# SKEAZN642 register map
Vendor: Freescale Semiconductor, Inc.; Series: Kinetis_EA; File version: 1.6
CPU: CM0PLUS r0p0, little endian, no MPU, no FPU, VTOR, 2 interrupt priority bits
Registers are 32-bit, read-write, reset 0x0 unless marked. A register's access mark holds for its fields unless they carry their own. Offsets are from the block's base; [hi:lo] are bit positions; {n}, {i} and the like mark numbered series; 'fields as' and 'values as' point back to an identical list.

## FTMRH_FlashConfig — Flash configuration field
Base 0x00000400; register names take the prefix NV_
{0x0+i} BACKKEY{i} 8-bit ro reset 0xFF (i=0..7) — Backdoor Comparison Key {i}
  [7:0] KEY — Backdoor Comparison Key.
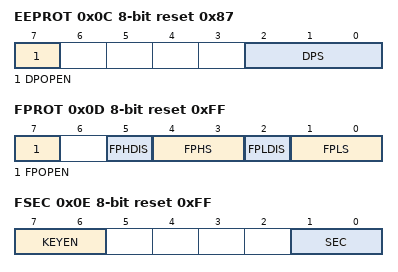
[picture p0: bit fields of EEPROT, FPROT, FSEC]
0x0C EEPROT 8-bit ro reset 0x87 — Non-volatile E-Flash Protection Register
  [7] DPOPEN
    0=Enables EEPROM memory protection; 1=Disables EEPROM memory protection
  [2:0] DPS
    0=Flash address range: 0x00_0000 - 0x00_001F; protected size: 32 bytes; 1=Flash address range: 0x00_0000 - 0x00_003F; protected size: 64 bytes; 2=Flash address range: 0x00_0000 - 0x00_005F; protected size: 96 bytes; 3=Flash address range: 0x00_0000 - 0x00_007F; protected size: 128 bytes; 4=Flash address range: 0x00_0000 - 0x00_009F; protected size: 160 bytes; 5=Flash address range: 0x00_0000 - 0x00_00BF; protected size: 192 bytes; 6=Flash address range: 0x00_0000 - 0x00_00DF; protected size: 224 bytes; 7=Flash address range: 0x00_0000 - 0x00_00FF; protected size: 256 bytes
0x0D FPROT 8-bit ro reset 0xFF — Non-volatile P-Flash Protection Register
  [7] FPOPEN
    0=FPHDIS and FPLDIS bits define unprotected address ranges as specified by the corresponding FPHS and FPLS bits FPROT1.1; 1=FPHDIS and FPLDIS bits enable protection for the address range specified by the corresponding FPHS and FPLS bits
  [5] FPHDIS
    0=Protection/Unprotection enabled; 1=Protection/Unprotection disabled
  [4:3] FPHS
    0=Address range: 0x00_7C00-0x00_7FFF; protected size: 1 KB; 1=Address range: 0x00_7800-0x00_7FFF; protected size: 2 KB; 2=Address range: 0x00_7000-0x00_7FFF; protected size: 4 KB; 3=Address range: 0x00_6000-0x00_7FFF; protected size: 8 KB
  [2] FPLDIS
    values as FPHDIS
  [1:0] FPLS
    0=Address range: 0x00_0000-0x00_07FF; protected size: 2 KB; 1=Address range: 0x00_0000-0x00_0FFF; protected size: 4 KB; 2=Address range: 0x00_0000-0x00_1FFF; protected size: 8 KB; 3=Address range: 0x00_0000-0x00_3FFF; protected size: 16 KB
0x0E FSEC 8-bit ro reset 0xFF — Non-volatile Flash Security Register
  [7:6] KEYEN — Backdoor Key Security Enable
    2=Backdoor key access enabled; 3=Backdoor key access disabled
  [1:0] SEC — Flash Security
    2=MCU security status is unsecure; 3=MCU security status is secure
0x0F FOPT 8-bit ro reset 0xFF — Non-volatile Flash Option Register

## IRQ — Interrupt
Base 0x40031000; register names take the prefix IRQ_
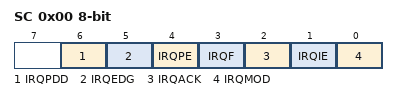
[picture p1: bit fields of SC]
0x00 SC 8-bit — Interrupt Pin Request Status and Control Register
  [6] IRQPDD — Interrupt Request (IRQ) Pull Device Disable
    0=IRQ pull device enabled if IRQPE = 1; 1=IRQ pull device disabled if IRQPE = 1
  [5] IRQEDG — Interrupt Request (IRQ) Edge Select
    0=IRQ is falling-edge or falling-edge/low-level sensitive; 1=IRQ is rising-edge or rising-edge/high-level sensitive
  [4] IRQPE — IRQ Pin Enable
    0=IRQ pin function is disabled; 1=IRQ pin function is enabled
  [3] IRQF ro — IRQ Flag
    0=No IRQ request; 1=IRQ event is detected
  [2] IRQACK wo — IRQ Acknowledge
  [1] IRQIE — IRQ Interrupt Enable
    0=Interrupt request when IRQF set is disabled (use polling); 1=Interrupt requested whenever IRQF = 1
  [0] IRQMOD — IRQ Detection Mode
    0=IRQ event is detected only on falling/rising edges; 1=IRQ event is detected on falling/rising edges and low/high levels

## CRC — Cyclic Redundancy Check
Base 0x40032000; register names take the prefix CRC_
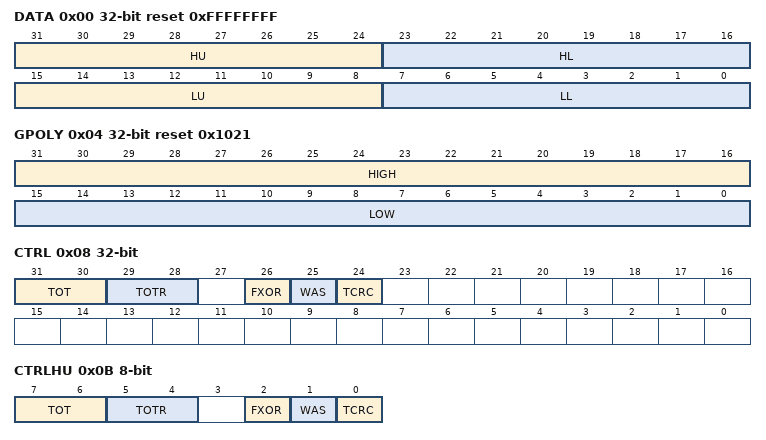
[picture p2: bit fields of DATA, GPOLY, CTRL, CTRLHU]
0x00 DATA reset 0xFFFFFFFF (CRC view) — CRC Data register
  [31:24] HU — CRC High Upper Byte
  [23:16] HL — CRC High Lower Byte
  [15:8] LU — CRC Low Upper Byte
  [7:0] LL — CRC Low Lower Byte
0x00 DATAL 16-bit reset 0xFFFF (CRC view) — CRC_DATAL register.
  [15:0] DATAL — DATAL stores the lower 16 bits of the 16/32 bit CRC
0x00 DATALL 8-bit reset 0xFF (CRC view) — CRC_DATALL register.
  [7:0] DATALL — CRCLL stores the first 8 bits of the 32 bit DATA
0x01 DATALU 8-bit reset 0xFF — CRC_DATALU register.
  [7:0] DATALU — DATALL stores the second 8 bits of the 32 bit CRC
0x02 DATAH 16-bit reset 0xFFFF (CRC view) — CRC_DATAH register.
  [15:0] DATAH — DATAH stores the high 16 bits of the 16/32 bit CRC
0x02 DATAHL 8-bit reset 0xFF (CRC view) — CRC_DATAHL register.
  [7:0] DATAHL — DATAHL stores the third 8 bits of the 32 bit CRC
0x03 DATAHU 8-bit reset 0xFF — CRC_DATAHU register.
  [7:0] DATAHU — DATAHU stores the fourth 8 bits of the 32 bit CRC
0x04 GPOLY reset 0x1021 (CRC view) — CRC Polynomial register
  [31:16] HIGH — High Polynominal Half-word
  [15:0] LOW — Low Polynominal Half-word
0x04 GPOLYL 16-bit reset 0xFFFF (CRC view) — CRC_GPOLYL register.
  [15:0] GPOLYL — POLYL stores the lower 16 bits of the 16/32 bit CRC polynomial value
0x04 GPOLYLL 8-bit reset 0xFF (CRC view) — CRC_GPOLYLL register.
  [7:0] GPOLYLL — POLYLL stores the first 8 bits of the 32 bit CRC
0x05 GPOLYLU 8-bit reset 0xFF — CRC_GPOLYLU register.
  [7:0] GPOLYLU — POLYLL stores the second 8 bits of the 32 bit CRC
0x06 GPOLYH 16-bit reset 0xFFFF (CRC view) — CRC_GPOLYH register.
  [15:0] GPOLYH — POLYH stores the high 16 bits of the 16/32 bit CRC polynomial value
0x06 GPOLYHL 8-bit reset 0xFF (CRC view) — CRC_GPOLYHL register.
  [7:0] GPOLYHL — POLYHL stores the third 8 bits of the 32 bit CRC
0x07 GPOLYHU 8-bit reset 0xFF — CRC_GPOLYHU register.
  [7:0] GPOLYHU — POLYHU stores the fourth 8 bits of the 32 bit CRC
0x08 CTRL — CRC Control register
  [31:30] TOT — Type Of Transpose For Writes
    0=No transposition; 1=Bits in bytes are transposed; bytes are not transposed; 2=Both bits in bytes and bytes are transposed; 3=Only bytes are transposed; no bits in a byte are transposed
  [29:28] TOTR — Type Of Transpose For Read
    values as TOT
  [26] FXOR — Complement Read Of CRC Data Register
    0=No XOR on reading; 1=Invert or complement the read value of the CRC Data register
  [25] WAS — Write CRC Data Register As Seed
    0=Writes to the CRC data register are data values; 1=Writes to the CRC data register are seed values
  [24] TCRC
    0=16-bit CRC protocol; 1=32-bit CRC protocol
0x0B CTRLHU 8-bit — CRC_CTRLHU register.
  [7:6] TOT
    0=No Transposition; 1=Bits in bytes are transposed, bytes are not transposed; 2=Both bits in bytes and bytes are transposed; 3=Only bytes are transposed; no bits in a byte are transposed
  [5:4] TOTR
    values as TOT
  [2] FXOR
    0=No XOR on reading; 1=Invert or complement the read value of CRC data register
  [1] WAS
    0=Writes to CRC data register are data values; 1=Writes to CRC data reguster are seed values
  [0] TCRC
    0=16-bit CRC protocol; 1=32-bit CRC protocol
